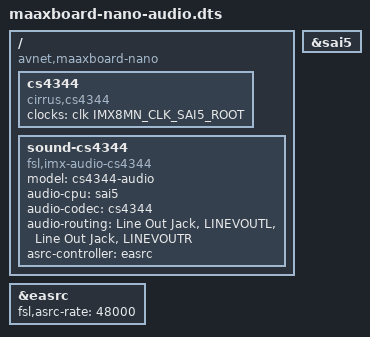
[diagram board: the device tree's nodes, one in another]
/*
 * Copyright 2021 AVNET
 *
 * This program is free software; you can redistribute it and/or
 * modify it under the terms of the GNU General Public License
 * as published by the Free Software Foundation; either version 2
 * of the License, or (at your option) any later version.
 *
 * This program is distributed in the hope that it will be useful,
 * but WITHOUT ANY WARRANTY; without even the implied warranty of
 * MERCHANTABILITY or FITNESS FOR A PARTICULAR PURPOSE.  See the
 * GNU General Public License for more details.
 */

/dts-v1/;
/plugin/;

#include <dt-bindings/clock/imx8mn-clock.h>

/ {
	compatible = "avnet,maaxboard-nano", "fsl,imx8mn";

	fragment@0 {
		target = <&sai5>;
		__overlay__ {
			status = "okay";
		};
	};
	
	fragment@1 {
		target = <&easrc>;
		__overlay__ {
			fsl,asrc-rate  = <48000>;
			status = "okay";
		};
	};

	fragment@2 {
		target-path = "/";
		__overlay__ {
			cs4344: cs4344 {
				compatible = "cirrus,cs4344";
				clocks = <&clk IMX8MN_CLK_SAI5_ROOT>;
				clock-names = "mclk";
			};

			sound-cs4344 {
				compatible = "fsl,imx-audio-cs4344";
				model = "cs4344-audio";
				audio-cpu = <&sai5>;
				audio-codec = <&cs4344>;
				audio-routing =
					"Line Out Jack", "LINEVOUTL",
					"Line Out Jack", "LINEVOUTR";
				asrc-controller = <&easrc>;
			};
		};
	};
};
